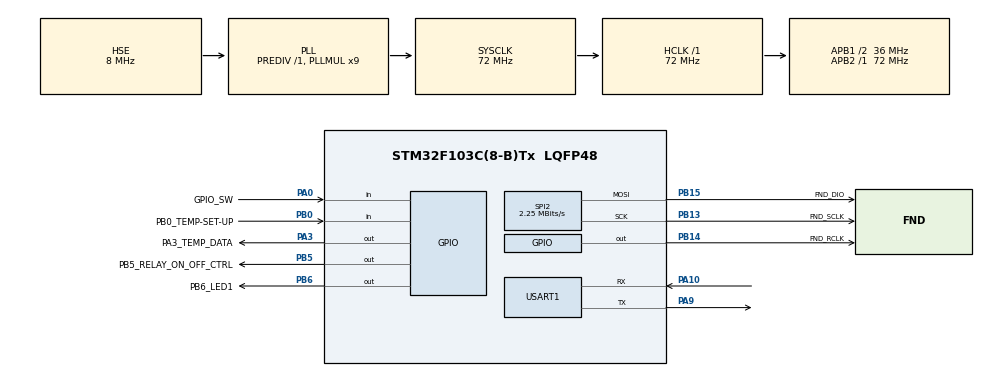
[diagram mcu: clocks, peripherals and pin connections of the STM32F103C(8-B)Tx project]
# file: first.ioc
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Mcu.Family=STM32F1
Mcu.Name=STM32F103C(8-B)Tx
Mcu.Package=LQFP48
NVIC.PriorityGroup=NVIC_PRIORITYGROUP_4
NVIC.TIM2_IRQn=true\:0\:0\:false\:false\:true\:true\:true\:true
PA0-WKUP.GPIO_Label=GPIO_SW
PA0-WKUP.GPIO_PuPd=GPIO_PULLUP
PA0-WKUP.Signal=GPIO_Input
PA10.Mode=Asynchronous
PA10.Signal=USART1_RX
PA13.Mode=Serial_Wire
PA13.Signal=SYS_JTMS-SWDIO
PA14.Mode=Serial_Wire
PA14.Signal=SYS_JTCK-SWCLK
PA3.GPIO_Label=PA3_TEMP_DATA
PA3.GPIO_ModeDefaultOutputPP=GPIO_MODE_OUTPUT_PP
PA3.GPIO_PuPd=GPIO_PULLUP
PA3.GPIO_Speed=GPIO_SPEED_FREQ_HIGH
PA3.PinState=GPIO_PIN_SET
PA3.Signal=GPIO_Output
PA5.Signal=SPI1_SCK
PA6.Signal=SPI1_MISO
PA7.Signal=SPI1_MOSI
PA9.Mode=Asynchronous
PA9.Signal=USART1_TX
PB0.GPIO_Label=PB0_TEMP-SET-UP
PB0.GPIO_PuPd=GPIO_PULLUP
PB0.Signal=GPIO_Input
PB13.GPIO_Label=FND_SCLK
PB13.Mode=TX_Only_Simplex_Unidirect_Master
PB13.Signal=SPI2_SCK
PB14.GPIO_Label=FND_RCLK
PB14.GPIO_PuPd=GPIO_NOPULL
PB14.PinState=GPIO_PIN_RESET
PB14.Signal=GPIO_Output
PB15.GPIO_Label=FND_DIO
PB15.Mode=TX_Only_Simplex_Unidirect_Master
PB15.Signal=SPI2_MOSI
PB5.GPIO_Label=PB5_RELAY_ON_OFF_CTRL
PB5.GPIO_PuPd=GPIO_PULLDOWN
PB5.GPIO_Speed=GPIO_SPEED_FREQ_HIGH
PB5.Signal=GPIO_Output
PB6.GPIO_Label=PB6_LED1
PB6.GPIO_PuPd=GPIO_PULLUP
PB6.PinState=GPIO_PIN_SET
PB6.Signal=GPIO_Output
PC14-OSC32_IN.Mode=LSE-External-Oscillator
PC14-OSC32_IN.Signal=RCC_OSC32_IN
PC15-OSC32_OUT.Mode=LSE-External-Oscillator
PC15-OSC32_OUT.Signal=RCC_OSC32_OUT
PD0-OSC_IN.Mode=HSE-External-Oscillator
PD0-OSC_IN.Signal=RCC_OSC_IN
PD1-OSC_OUT.Mode=HSE-External-Oscillator
PD1-OSC_OUT.Signal=RCC_OSC_OUT
ProjectManager.HeapSize=0x200
ProjectManager.StackSize=0x400
ProjectManager.TargetToolchain=STM32CubeIDE
RCC.AHBFreq_Value=72000000
RCC.APB1CLKDivider=RCC_HCLK_DIV2
RCC.APB1Freq_Value=36000000
RCC.APB1TimFreq_Value=72000000
RCC.APB2Freq_Value=72000000
RCC.APB2TimFreq_Value=72000000
RCC.HCLKFreq_Value=72000000
RCC.PLLMUL=RCC_PLL_MUL9
RCC.PLLSourceVirtual=RCC_PLLSOURCE_HSE
RCC.SYSCLKFreq_VALUE=72000000
RCC.SYSCLKSource=RCC_SYSCLKSOURCE_PLLCLK
RCC.USBFreq_Value=72000000
SPI2.BaudRatePrescaler=SPI_BAUDRATEPRESCALER_16
SPI2.CLKPolarity=SPI_POLARITY_HIGH
SPI2.CalculateBaudRate=2.25 MBits/s
SPI2.Direction=SPI_DIRECTION_2LINES
SPI2.Mode=SPI_MODE_MASTER
SPI2.VirtualType=VM_MASTER
TIM2.AutoReloadPreload=TIM_AUTORELOAD_PRELOAD_DISABLE
TIM2.Period=1999
TIM2.Prescaler=(72-1)
USART1.VirtualMode=VM_ASYNC
VP_TIM2_VS_ClockSourceINT.Mode=Internal
board=custom

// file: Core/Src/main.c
/* USER CODE BEGIN Header */
/**
  ******************************************************************************
  * @file           : main.c
  * @brief          : Main program body
  ******************************************************************************
  * @attention
  *
  * Copyright (c) 2025 STMicroelectronics.
  * All rights reserved.
  *
  * This software is licensed under terms that can be found in the LICENSE file
  * in the root directory of this software component.
  * If no LICENSE file comes with this software, it is provided AS-IS.
  *
  ******************************************************************************
  */
/* USER CODE END Header */
#include "main.h"
#include "spi.h"
#include "tim.h"
#include "usart.h"
#include "gpio.h"

/* USER CODE BEGIN Includes */
#include <stdio.h>
#include "fnd_controller.h"
#include "ds18b20.h"
#include "heaterController.h"
/* USER CODE END Includes */

void SystemClock_Config(void);

/* USER CODE BEGIN 0 */
int _write(int file, char * p, int len) {
	HAL_UART_Transmit(&huart1,(uint8_t *)p, len, 10);
	return len;
}
/* USER CODE END 0 */

int main(void)
{

  /* MCU Configuration--------------------------------------------------------*/

  /* Reset of all peripherals, Initializes the Flash interface and the Systick. */
  HAL_Init();

  /* Configure the system clock */
  SystemClock_Config();

  /* Initialize all configured peripherals */
  MX_GPIO_Init();
  MX_USART1_UART_Init();
  MX_SPI2_Init();
  MX_TIM2_Init();
  /* USER CODE BEGIN 2 */
  init_fnd(&hspi2);
  Ds18b20_Init();
//  HAL_TIM_Base_Start_IT(&htim2);
  /* USER CODE END 2 */

  /* Infinite loop */
  /* USER CODE BEGIN WHILE */
  while (1)
    {
	  Ds18b20_ManualConvert(); // 온도 정보 가져오고
//	  digit4_temper((int)(ds18b20[0].Temperature * 10), 1);
//	  HAL_GPIO_TogglePin(PB5_RELAY_ON_OFF_CTRL_GPIO_Port, GPIO_PIN_5);
//	  HAL_Delay(2000);
	  if(getCurrentTemper() > 50 && getHeaterState() == t_ON) {
		  heaterControll(t_OFF);
	  } else if(getCurrentTemper() < 45 && getHeaterState() == t_OFF) {
		  heaterControll(t_ON);
	  }
    /* USER CODE END WHILE */

    }
}

void SystemClock_Config(void)
{
  RCC_OscInitTypeDef RCC_OscInitStruct = {0};
  RCC_ClkInitTypeDef RCC_ClkInitStruct = {0};

  /** Initializes the RCC Oscillators according to the specified parameters
  * in the RCC_OscInitTypeDef structure.
  */
  RCC_OscInitStruct.OscillatorType = RCC_OSCILLATORTYPE_HSE;
  RCC_OscInitStruct.HSEState = RCC_HSE_ON;
  RCC_OscInitStruct.HSEPredivValue = RCC_HSE_PREDIV_DIV1;
  RCC_OscInitStruct.HSIState = RCC_HSI_ON;
  RCC_OscInitStruct.PLL.PLLState = RCC_PLL_ON;
  RCC_OscInitStruct.PLL.PLLSource = RCC_PLLSOURCE_HSE;
  RCC_OscInitStruct.PLL.PLLMUL = RCC_PLL_MUL9;
  if (HAL_RCC_OscConfig(&RCC_OscInitStruct) != HAL_OK)
  {
    Error_Handler();
  }

  /** Initializes the CPU, AHB and APB buses clocks
  */
  RCC_ClkInitStruct.ClockType = RCC_CLOCKTYPE_HCLK|RCC_CLOCKTYPE_SYSCLK
                              |RCC_CLOCKTYPE_PCLK1|RCC_CLOCKTYPE_PCLK2;
  RCC_ClkInitStruct.SYSCLKSource = RCC_SYSCLKSOURCE_PLLCLK;
  RCC_ClkInitStruct.AHBCLKDivider = RCC_SYSCLK_DIV1;
  RCC_ClkInitStruct.APB1CLKDivider = RCC_HCLK_DIV2;
  RCC_ClkInitStruct.APB2CLKDivider = RCC_HCLK_DIV1;

  if (HAL_RCC_ClockConfig(&RCC_ClkInitStruct, FLASH_LATENCY_2) != HAL_OK)
  {
    Error_Handler();
  }
}

void Error_Handler(void)
{
  __disable_irq();
  while (1)
  {
  }
}
